AUTOSAR XML (schema 4-2-1)
package /VehicleProject
  system System
package /NM
  nm config NmConfig: can-nm-cluster-coupling=coupled-cluster=CAN00_CAN
    can nm cluster CAN00_CAN: communication-cluster=CAN00, nm-channel-id=0, nm-msg-cycle-time=0.1, nm-network-timeout=1, nm-repeat-message-time=0.4, nm-user-data-length=6, nm-wait-bus-sleep-time=0.75
      can nm node MyECU: controller=CT_CAN00, nm-if-ecu=MyECU_CAN, nm-node-id=0, rx-nm-pdu=msg_nm_RearECU_oCAN00, tx-nm-pdu=msg_nm_MyECU_oCAN00, nm-msg-cycle-offset=0, nm-msg-reduced-time=0.05, nm-range-config={lower-can-id=1024, upper-can-id=1087}
      can nm node RearECU: nm-if-ecu=RearECU_CAN, nm-node-id=1, rx-nm-pdu=msg_nm_MyECU_oCAN00, tx-nm-pdu=msg_nm_RearECU_oCAN00, nm-msg-cycle-offset=0, nm-msg-reduced-time=0.05, nm-range-config={lower-can-id=1024, upper-can-id=1087}
      can nm node Tester: nm-if-ecu=Tester_CAN, nm-node-id=0, nm-passive-mode-enabled=true, nm-msg-cycle-offset=0, nm-msg-reduced-time=0.05, nm-range-config={lower-can-id=1024, upper-can-id=1087}
    nm-if-ecus:
      nm ecu MyECU_CAN: ecu-instance=MyECU, nm-node-id-enabled=true, nm-user-data-enabled=true
      nm ecu RearECU_CAN: nm-node-id-enabled=true, nm-user-data-enabled=true
      nm ecu Tester_CAN: nm-node-id-enabled=true, nm-passive-mode-enabled=true, nm-user-data-enabled=true
package /TP
  can tp config CAN00_CAN: communication-cluster=CAN00, can-tp-ecu{cycle-time-main-function=0.005, ecu-instance=MyECU}
    can tp channel TPCH: channel-id=0, channel-mode=FULL-DUPLEX-MODE
    can-tp-connection addressing-format=STANDARD, can-tp-channel=TPCH, data-pdu=msg_diag_RequestGlobal_Tp_oCAN00, receiver=TN_MyECU, ta-type=FUNCTIONAL, tp-sdu=msg_diag_RequestGlobal_oCAN00, transmitter=TN_Tester:
      ident msg_diag_RequestGlobal_oTN_Tester
    can-tp-connection addressing-format=STANDARD, can-tp-channel=TPCH, data-pdu=msg_diag_Request_MyECU_Tp_oCAN00, flow-control-pdu=msg_diag_Response_MyECU_Tp_oCAN00, receiver=TN_MyECU, ta-type=PHYSICAL, tp-sdu=msg_diag_Request_MyECU_oCAN00, transmitter=TN_Tester:
      ident msg_diag_Request_MyECU_oTN_MyECU
    can-tp-connection addressing-format=STANDARD, can-tp-channel=TPCH, data-pdu=msg_diag_Response_MyECU_Tp_oCAN00, flow-control-pdu=msg_diag_Request_MyECU_Tp_oCAN00, receiver=TN_Tester, ta-type=PHYSICAL, tp-sdu=msg_diag_Response_MyECU_oCAN00, transmitter=TN_MyECU:
      ident msg_diag_Response_MyECU_oTN_MyECU
    can tp node TN_MyECU: connector=CN_CAN00
    can tp node TN_Tester
package /Cluster
  can cluster CAN00: protocol-name=CAN
    can physical channel CHNL: comm-connectors=CN_CAN00
      frame msg_diag_Request_MyECU_oCAN00: id 0x610, to MyECU, frame-length=8, can-addressing-mode=STANDARD
        n pdu msg_diag_Request_MyECU_Tp_oCAN00: length=8
      frame msg_diag_RequestGlobal_oCAN00: id 0x614, to MyECU, frame-length=8, can-addressing-mode=STANDARD
        n pdu msg_diag_RequestGlobal_Tp_oCAN00: length=8
      frame msg_diag_Response_MyECU_oCAN00: id 0x612, from MyECU, frame-length=8, can-addressing-mode=STANDARD
        n pdu msg_diag_Response_MyECU_Tp_oCAN00: length=8
      frame msg_MyECU_Lamp_oCAN00: id 0x511, from MyECU, frame-length=8, can-addressing-mode=STANDARD
        pdu msg_MyECU_Lamp_oCAN00: length=8, minimum-delay=0, transmission-mode-false-timing=cyclic-timing={time-offset=0, time-period=0.1}, transmission-mode-true-timing=cyclic-timing={time-offset=0, time-period=0.1}, unused-bit-pattern=0
          signal sig_LampCnt_omsg_MyECU_Lamp_oCAN00: start 7, 8 bit, big-endian, init-value=0, base-type=uint8, data-constr=DC_sig_LampCnt, transfer-property=PENDING
      frame msg_nm_MyECU_oCAN00: id 0x400, from MyECU, frame-length=8, can-addressing-mode=STANDARD
        nm pdu msg_nm_MyECU_oCAN00: length=8, unused-bit-pattern=0
      frame msg_nm_RearECU_oCAN00: id 0x401, to MyECU, frame-length=8, can-addressing-mode=STANDARD
        nm pdu msg_nm_RearECU_oCAN00: length=8, unused-bit-pattern=0
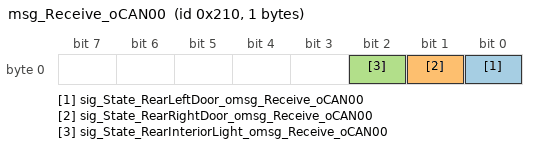
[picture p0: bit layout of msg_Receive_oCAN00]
      frame msg_Receive_oCAN00: id 0x210, to MyECU, frame-length=1, can-addressing-mode=STANDARD
        pdu msg_Receive_oCAN00: length=1, minimum-delay=0, transmission-mode-false-timing=cyclic-timing={time-offset=0, time-period=0.1}, transmission-mode-true-timing=cyclic-timing={time-offset=0, time-period=0.1}, unused-bit-pattern=0
          signal sig_State_RearLeftDoor_omsg_Receive_oCAN00: start 0, 1 bit, little-endian, init-value=0, base-type=boolean, data-constr=DC_sig_State_RearLeftDoor, transfer-property=PENDING, to MyECU
          signal sig_State_RearRightDoor_omsg_Receive_oCAN00: start 1, 1 bit, little-endian, init-value=0, base-type=boolean, data-constr=DC_sig_State_RearRightDoor, transfer-property=PENDING, to MyECU
          signal sig_State_RearInteriorLight_omsg_Receive_oCAN00: start 2, 1 bit, little-endian, init-value=0, base-type=boolean, data-constr=DC_sig_State_RearInteriorLight, transfer-property=PENDING, to MyECU
      frame msg_Transmit_oCAN00: id 0x200, from MyECU, frame-length=1, can-addressing-mode=STANDARD
        pdu msg_Transmit_oCAN00: length=1, minimum-delay=0, transmission-mode-false-timing=cyclic-timing={time-offset=0, time-period=0.1}, transmission-mode-true-timing=cyclic-timing={time-offset=0, time-period=0.1}, unused-bit-pattern=0
          signal sig_RearInteriorLight_omsg_Transmit_oCAN00: start 0, 1 bit, little-endian, init-value=0, base-type=boolean, data-constr=DC_sig_RearInteriorLight, transfer-property=PENDING
      frame VCUHV_Receive_oCAN00: id 0x11, to MyECU, frame-length=5, can-addressing-mode=STANDARD
        pdu VCUHV_Receive_oCAN00: length=5, minimum-delay=0, unused-bit-pattern=0
          signal read_SelfCheck_Status_oVCUHV_Receive_oCAN00: start 0, 1 bit, little-endian, init-value=0, base-type=boolean, data-constr=DC_read_SelfCheck_Status, transfer-property=PENDING, to MyECU
          signal read_VehicleFaultLevel_oVCUHV_Receive_oCAN00: start 1, 1 bit, little-endian, init-value=0, base-type=boolean, data-constr=DC_read_VehicleFaultLevel, transfer-property=PENDING, to MyECU
          signal read_BmsMainNegativeRelay_Status_oVCUHV_Receive_oCAN00: start 2, 1 bit, little-endian, init-value=0, base-type=boolean, data-constr=DC_read_BmsMainNegativeRelay_Status, transfer-property=PENDING, to MyECU
          signal read_SlowChargePlug_Status_oVCUHV_Receive_oCAN00: start 4, 1 bit, little-endian, init-value=0, base-type=boolean, data-constr=DC_read_SlowChargePlug_Status, transfer-property=PENDING, to MyECU
          signal read_FastChargePlug_Status_oVCUHV_Receive_oCAN00: start 5, 1 bit, little-endian, init-value=0, base-type=boolean, data-constr=DC_read_FastChargePlug_Status, transfer-property=PENDING, to MyECU
          signal read_KeyStartSwitch_Signal_oVCUHV_Receive_oCAN00: start 6, 1 bit, little-endian, init-value=0, base-type=boolean, data-constr=DC_read_KeyStartSwitch_Signal, transfer-property=PENDING, to MyECU
          signal read_ActualGear_Status_oVCUHV_Receive_oCAN00: start 8, 1 bit, little-endian, init-value=0, base-type=boolean, data-constr=DC_read_ActualGear_Status, transfer-property=PENDING, to MyECU
          signal read_BrakePedal_Status_oVCUHV_Receive_oCAN00: start 9, 1 bit, little-endian, init-value=0, base-type=boolean, data-constr=DC_read_BrakePedal_Status, transfer-property=PENDING, to MyECU
          signal read_PduMainPrechargeRelay_oVCUHV_Receive_oCAN00: start 11, 1 bit, little-endian, init-value=0, base-type=boolean, data-constr=DC_read_PduMainPrechargeRelay, transfer-property=PENDING, to MyECU
          signal read_PduMainRelay_Status_oVCUHV_Receive_oCAN00: start 12, 1 bit, little-endian, init-value=0, base-type=boolean, data-constr=DC_read_PduMainRelay_Status, transfer-property=PENDING, to MyECU
          signal read_McuWorking_Status_oVCUHV_Receive_oCAN00: start 13, 1 bit, little-endian, init-value=0, base-type=boolean, data-constr=DC_read_McuWorking_Status, transfer-property=PENDING, to MyECU
          signal read_KeyONSwitch_Signal_oVCUHV_Receive_oCAN00: start 14, 2 bit, little-endian, init-value=0, base-type=uint8, data-constr=DC_read_KeyONSwitch_Signal, transfer-property=PENDING, to MyECU
          signal read_BmsBattery_SocValue_oVCUHV_Receive_oCAN00: start 16, 6 bit, little-endian, init-value=0, base-type=uint8, data-constr=DC_read_BmsBattery_SocValue, transfer-property=PENDING, to MyECU
          signal read_BmsRelayOff_Request_oVCUHV_Receive_oCAN00: start 22, 1 bit, little-endian, init-value=0, base-type=boolean, data-constr=DC_read_BmsRelayOff_Request, transfer-property=PENDING, to MyECU
          signal read_BmsMainNegativeRelayClosed_oVCUHV_Receive_oCAN00: start 23, 1 bit, little-endian, init-value=0, base-type=boolean, data-constr=DC_read_BmsMainNegativeRelayClosed, transfer-property=PENDING, to MyECU
          signal read_DcdcWorking_Status_oVCUHV_Receive_oCAN00: start 24, 1 bit, little-endian, init-value=0, base-type=boolean, data-constr=DC_read_DcdcWorking_Status, transfer-property=PENDING, to MyECU
          signal read_AcceleratorPedal_Opening_oVCUHV_Receive_oCAN00: start 25, 7 bit, little-endian, init-value=0, base-type=uint8, data-constr=DC_read_AcceleratorPedal_Opening, transfer-property=PENDING, to MyECU
          signal read_BmsBatteryTotal_Current_oVCUHV_Receive_oCAN00: start 32, 1 bit, little-endian, init-value=0, base-type=boolean, data-constr=DC_read_BmsBatteryTotal_Current, transfer-property=PENDING, to MyECU
          signal read_VehicleSpeed_Kph_oVCUHV_Receive_oCAN00: start 33, 7 bit, little-endian, init-value=0, base-type=uint8, data-constr=DC_read_VehicleSpeed_Kph, transfer-property=PENDING, to MyECU
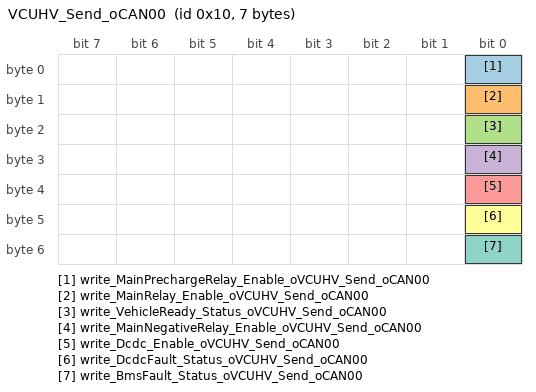
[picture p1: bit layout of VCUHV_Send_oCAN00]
      frame VCUHV_Send_oCAN00: id 0x10, from MyECU, frame-length=7, can-addressing-mode=STANDARD
        pdu VCUHV_Send_oCAN00: length=7, minimum-delay=0, unused-bit-pattern=0
          signal write_MainPrechargeRelay_Enable_oVCUHV_Send_oCAN00: start 0, 1 bit, little-endian, init-value=0, base-type=boolean, data-constr=DC_write_MainPrechargeRelay_Enable, transfer-property=PENDING
          signal write_MainRelay_Enable_oVCUHV_Send_oCAN00: start 8, 1 bit, little-endian, init-value=0, base-type=boolean, data-constr=DC_write_MainRelay_Enable, transfer-property=PENDING
          signal write_VehicleReady_Status_oVCUHV_Send_oCAN00: start 16, 1 bit, little-endian, init-value=0, base-type=boolean, data-constr=DC_write_VehicleReady_Status, transfer-property=PENDING
          signal write_MainNegativeRelay_Enable_oVCUHV_Send_oCAN00: start 24, 1 bit, little-endian, init-value=0, base-type=boolean, data-constr=DC_write_MainNegativeRelay_Enable, transfer-property=PENDING
          signal write_Dcdc_Enable_oVCUHV_Send_oCAN00: start 32, 1 bit, little-endian, init-value=0, base-type=boolean, data-constr=DC_write_Dcdc_Enable, transfer-property=PENDING
          signal write_DcdcFault_Status_oVCUHV_Send_oCAN00: start 40, 1 bit, little-endian, init-value=0, base-type=boolean, data-constr=DC_write_DcdcFault_Status, transfer-property=PENDING
          signal write_BmsFault_Status_oVCUHV_Send_oCAN00: start 48, 1 bit, little-endian, init-value=0, base-type=boolean, data-constr=DC_write_BmsFault_Status, transfer-property=PENDING
      pdu triggering PT_msg_diag_Request_MyECU: pdu=msg_diag_Request_MyECU_oCAN00, to MyECU
      pdu triggering PT_msg_diag_RequestGlobal: pdu=msg_diag_RequestGlobal_oCAN00, to MyECU
      pdu triggering PT_msg_diag_Response_MyECU: pdu=msg_diag_Response_MyECU_oCAN00, from MyECU
package /ECU
  ecu instance MyECU: associated-com-i-pdu-group=[MyECU_oCAN00_Rx, MyECU_oCAN00_Tx]
    can communication controller CT_CAN00
    can communication connector CN_CAN00: comm-controller=CT_CAN00
package /IPDUGroup
  i signal i pdu group MyECU_oCAN00_Rx: communication-direction=IN, i-signal-i-pdus=[msg_Receive_oCAN00, VCUHV_Receive_oCAN00]
  i signal i pdu group MyECU_oCAN00_Tx: communication-direction=OUT, i-signal-i-pdus=[msg_MyECU_Lamp_oCAN00, msg_Transmit_oCAN00, VCUHV_Send_oCAN00]
package /PDU
  dcm i pdu msg_diag_Request_MyECU_oCAN00: length=8, diag-pdu-type=DIAG-REQUEST
  dcm i pdu msg_diag_RequestGlobal_oCAN00: length=7, diag-pdu-type=DIAG-REQUEST
  dcm i pdu msg_diag_Response_MyECU_oCAN00: length=8, diag-pdu-type=DIAG-RESPONSE
